AUTOSAR XML (schema 00046)
package /ComponentTypes
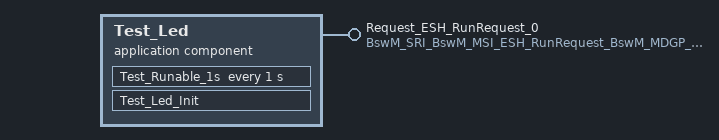
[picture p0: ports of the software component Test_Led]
  application sw component type Test_Led
    provide port Request_ESH_RunRequest_0: nonqueued-sender-com-spec=requestedMode, provided-interface=BswM_SRI_BswM_MSI_ESH_RunRequest_BswM_MDGP_ESH_RunRequest
    behavior Test_Led_InternalBehavior
      init event Test_Led_InitEvent: start-on-event=Test_Led_Init
      timing event TMT_1_Test_Runable_1s: start-on-event=Test_Runable_1s, period=1
      runnable Test_Runable_1s
      runnable Test_Led_Init
        data-send-points:
          access SEND_Request_ESH_RunRequest_0_requestedMode: accessed-variable=Request_ESH_RunRequest_0.requestedMode
  swc implementation Test_Led_Implementation: behavior=Test_Led_InternalBehavior
